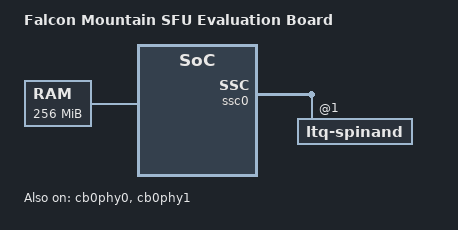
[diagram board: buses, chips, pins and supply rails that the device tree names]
/dts-v1/;
#include <dt-bindings/interrupt-controller/mips-gic.h>
#include <dt-bindings/clock/intel,falconmx-clk.h>
#include <dt-bindings/pinctrl/intel,equilibrium.h>
#include "falconmx.dtsi"
#include "prx220a_evm.dtsi"

/ {
	model = "Falcon Mountain SFU Evaluation Board";
	compatible = "intel,xprx220aeva", "intel,falconmx";

	chosen {
		/* bootargs = "earlycon=lantiq,0x16380000 nr_cpus=4 maxcpus=4 console=ttyLTQ0,115200 root=/dev/ram panic=1 init=/etc/preinit nocoherentio=1 clk_ignore_unused mem=94M@512M rcupdate.rcu_cpu_stall_suppress=1";*/
		stdout-path = "serial0";
	};

	memory@0 {
		device_type = "memory";
		reg = <0x20000000 0x10000000>; /* 256 MB */
	};
};

/* temporary disable qspi nand during bringup due to board issue,
   we use spi nand as fallback option */
&ssc0 {
	status = "okay";
	ltq-spinand@1 {
		status = "okay";
	};
};

&qspi0 {
	status = "disabled";
};

&cb0phy0 {
	mode = <1>; /*0-pcie, 1-xpcs*/
	status = "ok";
};

&cb0phy1 {
	mode = <1>; /*0-pcie, 1-xpcs*/
	status = "ok";
};

